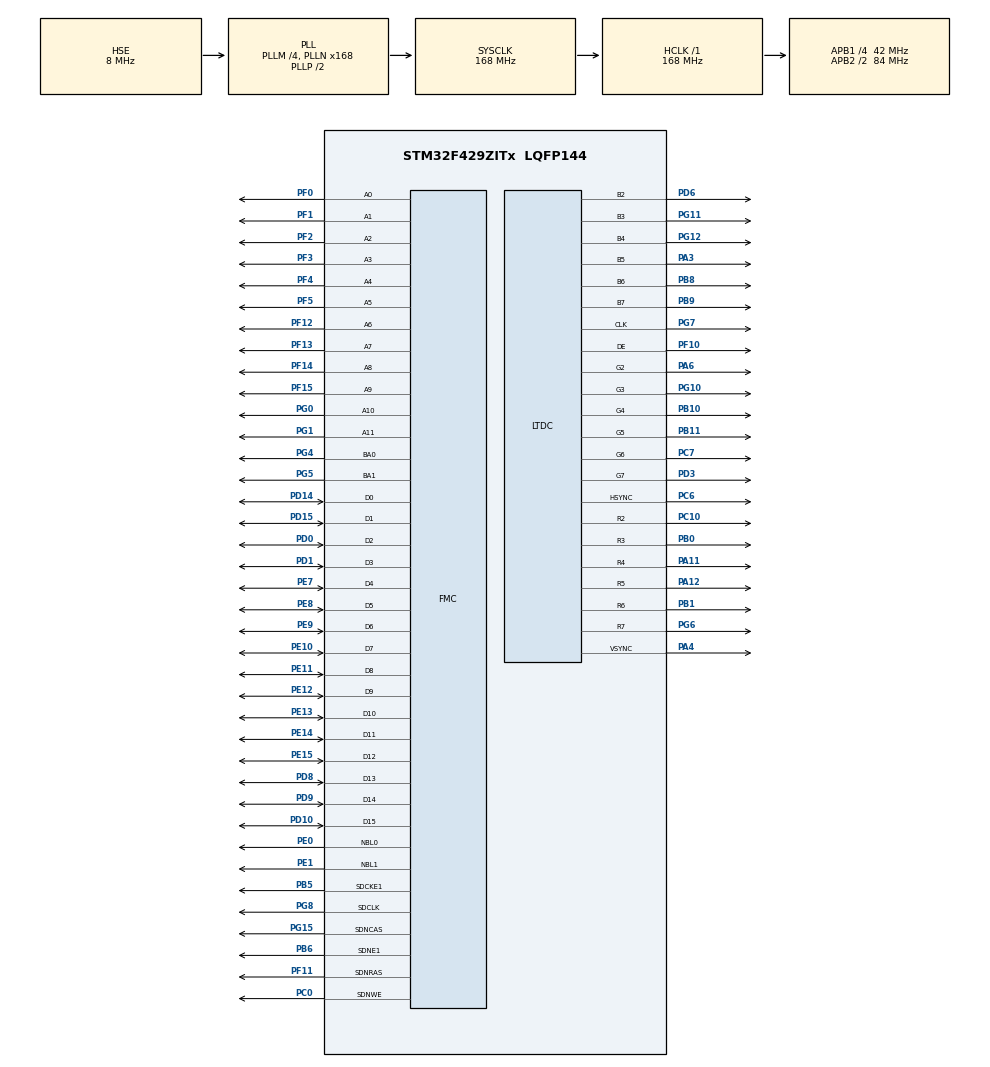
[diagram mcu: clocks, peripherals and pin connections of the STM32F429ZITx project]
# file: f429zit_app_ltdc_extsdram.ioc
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FMC.CASLatency1=FMC_SDRAM_CAS_LATENCY_3
FMC.ExitSelfRefreshDelay1=7
FMC.LoadToActiveDelay1=2
FMC.RCDDelay1=2
FMC.RPDelay1=2
FMC.RPDelay2=2
FMC.ReadPipeDelay1=FMC_SDRAM_RPIPE_DELAY_1
FMC.ReadPipeDelay2=FMC_SDRAM_RPIPE_DELAY_1
FMC.RowCycleDelay1=7
FMC.RowCycleDelay2=7
FMC.SDClockPeriod1=FMC_SDRAM_CLOCK_PERIOD_2
FMC.SDClockPeriod2=FMC_SDRAM_CLOCK_PERIOD_2
FMC.SelfRefreshTime1=4
FMC.WriteRecoveryTime1=3
LTDC.ActiveH=320
LTDC.ActiveW=240
LTDC.Alpha_L0=255
LTDC.BlendingFactor1_L0=LTDC_BLENDING_FACTOR1_PAxCA
LTDC.BlendingFactor2_L0=LTDC_BLENDING_FACTOR2_PAxCA
LTDC.HBP=20
LTDC.HFP=10
LTDC.HSync=10
LTDC.ImageHeight_L0=320
LTDC.ImageWidth_L0=240
LTDC.Layers=0
LTDC.PixelFormat_L0=LTDC_PIXEL_FORMAT_RGB565
LTDC.VFP=4
LTDC.VSync=2
LTDC.WindowX1_L0=240
LTDC.WindowY1_L0=320
Mcu.Family=STM32F4
Mcu.Name=STM32F429ZITx
Mcu.Package=LQFP144
NVIC.PriorityGroup=NVIC_PRIORITYGROUP_4
NVIC.TIM6_DAC_IRQn=true\:0\:0\:false\:false\:true\:false
NVIC.TimeBase=TIM6_DAC_IRQn
NVIC.TimeBaseIP=TIM6
PA11.Mode=RGB666
PA11.Signal=LTDC_R4
PA12.Mode=RGB666
PA12.Signal=LTDC_R5
PA13.Mode=Trace_Asynchronous_SW
PA13.Signal=SYS_JTMS-SWDIO
PA14.Mode=Trace_Asynchronous_SW
PA14.Signal=SYS_JTCK-SWCLK
PA3.Mode=RGB666
PA3.Signal=LTDC_B5
PA4.Mode=RGB666
PA4.Signal=LTDC_VSYNC
PA6.Mode=RGB666
PA6.Signal=LTDC_G2
PB0.Mode=RGB666
PB0.Signal=LTDC_R3
PB1.Mode=RGB666
PB1.Signal=LTDC_R6
PB10.Mode=RGB666
PB10.Signal=LTDC_G4
PB11.Mode=RGB666
PB11.Signal=LTDC_G5
PB3.Mode=Trace_Asynchronous_SW
PB3.Signal=SYS_JTDO-SWO
PB5.Mode=SdramChipSelect2_1
PB5.Signal=FMC_SDCKE1
PB6.Mode=SdramChipSelect2_1
PB6.Signal=FMC_SDNE1
PB8.Mode=RGB666
PB8.Signal=LTDC_B6
PB9.Mode=RGB666
PB9.Signal=LTDC_B7
PC0.Signal=FMC_SDNWE
PC10.Mode=RGB666
PC10.Signal=LTDC_R2
PC6.Mode=RGB666
PC6.Signal=LTDC_HSYNC
PC7.Mode=RGB666
PC7.Signal=LTDC_G6
PD0.Signal=FMC_D2_DA2
PD1.Signal=FMC_D3_DA3
PD10.Signal=FMC_D15_DA15
PD14.Signal=FMC_D0_DA0
PD15.Signal=FMC_D1_DA1
PD3.Mode=RGB666
PD3.Signal=LTDC_G7
PD6.Mode=RGB666
PD6.Signal=LTDC_B2
PD8.Signal=FMC_D13_DA13
PD9.Signal=FMC_D14_DA14
PE0.Signal=FMC_NBL0
PE1.Signal=FMC_NBL1
PE10.Signal=FMC_D7_DA7
PE11.Signal=FMC_D8_DA8
PE12.Signal=FMC_D9_DA9
PE13.Signal=FMC_D10_DA10
PE14.Signal=FMC_D11_DA11
PE15.Signal=FMC_D12_DA12
PE7.Signal=FMC_D4_DA4
PE8.Signal=FMC_D5_DA5
PE9.Signal=FMC_D6_DA6
PF0.Signal=FMC_A0
PF1.Signal=FMC_A1
PF10.Mode=RGB666
PF10.Signal=LTDC_DE
PF11.Signal=FMC_SDNRAS
PF12.Signal=FMC_A6
PF13.Signal=FMC_A7
PF14.Signal=FMC_A8
PF15.Signal=FMC_A9
PF2.Signal=FMC_A2
PF3.Signal=FMC_A3
PF4.Signal=FMC_A4
PF5.Signal=FMC_A5
PG0.Signal=FMC_A10
PG1.Signal=FMC_A11
PG10.Mode=RGB666
PG10.Signal=LTDC_G3
PG11.Mode=RGB666
PG11.Signal=LTDC_B3
PG12.Mode=RGB666
PG12.Signal=LTDC_B4
PG15.Signal=FMC_SDNCAS
PG4.Signal=FMC_A14_BA0
PG5.Signal=FMC_A15_BA1
PG6.Mode=RGB666
PG6.Signal=LTDC_R7
PG7.Mode=RGB666
PG7.Signal=LTDC_CLK
PG8.Signal=FMC_SDCLK
PH0/OSC_IN.Mode=HSE-External-Oscillator
PH0/OSC_IN.Signal=RCC_OSC_IN
PH1/OSC_OUT.Mode=HSE-External-Oscillator
PH1/OSC_OUT.Signal=RCC_OSC_OUT
ProjectManager.HeapSize=0x200
ProjectManager.StackSize=0x800
ProjectManager.TargetToolchain=TrueSTUDIO
RCC.48MHZClocksFreq_Value=84000000
RCC.AHBFreq_Value=168000000
RCC.APB1CLKDivider=RCC_HCLK_DIV4
RCC.APB1Freq_Value=42000000
RCC.APB1TimFreq_Value=84000000
RCC.APB2CLKDivider=RCC_HCLK_DIV2
RCC.APB2Freq_Value=84000000
RCC.APB2TimFreq_Value=168000000
RCC.CortexFreq_Value=168000000
RCC.HCLKFreq_Value=168000000
RCC.HSE_VALUE=8000000
RCC.HSI_VALUE=16000000
RCC.LSE_VALUE=32768
RCC.PLLM=4
RCC.PLLN=168
RCC.PLLSAIDivR=RCC_PLLSAIDIVR_4
RCC.PLLSAIN=60
RCC.PLLSAIR=5
RCC.PLLSourceVirtual=RCC_PLLSOURCE_HSE
RCC.SYSCLKFreq_VALUE=168000000
RCC.SYSCLKSource=RCC_SYSCLKSOURCE_PLLCLK
RCC.VCOOutputFreq_Value=336000000
SH.FMC_A0.0=FMC_A0,12b-sda1
SH.FMC_A1.0=FMC_A1,12b-sda1
SH.FMC_A10.0=FMC_A10,12b-sda1
SH.FMC_A11.0=FMC_A11,12b-sda1
SH.FMC_A14_BA0.0=FMC_BA0,FourSdramBanks1
SH.FMC_A15_BA1.0=FMC_BA1,FourSdramBanks1
SH.FMC_A2.0=FMC_A2,12b-sda1
SH.FMC_A3.0=FMC_A3,12b-sda1
SH.FMC_A4.0=FMC_A4,12b-sda1
SH.FMC_A5.0=FMC_A5,12b-sda1
SH.FMC_A6.0=FMC_A6,12b-sda1
SH.FMC_A7.0=FMC_A7,12b-sda1
SH.FMC_A8.0=FMC_A8,12b-sda1
SH.FMC_A9.0=FMC_A9,12b-sda1
SH.FMC_D0_DA0.0=FMC_D0,sd-16b-d1
SH.FMC_D10_DA10.0=FMC_D10,sd-16b-d1
SH.FMC_D11_DA11.0=FMC_D11,sd-16b-d1
SH.FMC_D12_DA12.0=FMC_D12,sd-16b-d1
SH.FMC_D13_DA13.0=FMC_D13,sd-16b-d1
SH.FMC_D14_DA14.0=FMC_D14,sd-16b-d1
SH.FMC_D15_DA15.0=FMC_D15,sd-16b-d1
SH.FMC_D1_DA1.0=FMC_D1,sd-16b-d1
SH.FMC_D2_DA2.0=FMC_D2,sd-16b-d1
SH.FMC_D3_DA3.0=FMC_D3,sd-16b-d1
SH.FMC_D4_DA4.0=FMC_D4,sd-16b-d1
SH.FMC_D5_DA5.0=FMC_D5,sd-16b-d1
SH.FMC_D6_DA6.0=FMC_D6,sd-16b-d1
SH.FMC_D7_DA7.0=FMC_D7,sd-16b-d1
SH.FMC_D8_DA8.0=FMC_D8,sd-16b-d1
SH.FMC_D9_DA9.0=FMC_D9,sd-16b-d1
SH.FMC_NBL0.0=FMC_NBL0,Sd2ByteEnable1
SH.FMC_NBL1.0=FMC_NBL1,Sd2ByteEnable1
SH.FMC_SDCLK.0=FMC_SDCLK,12b-sda1
SH.FMC_SDNCAS.0=FMC_SDNCAS,12b-sda1
SH.FMC_SDNRAS.0=FMC_SDNRAS,12b-sda1
SH.FMC_SDNWE.0=FMC_SDNWE,12b-sda1
VP_CRC_VS_CRC.Mode=CRC_Activate
VP_DMA2D_VS_DMA2D.Mode=DMA2D_Activate
VP_SYS_VS_tim6.Mode=TIM6
board=custom

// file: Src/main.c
/**
  ******************************************************************************
  * @file           : main.c
  * @brief          : Main program body
  ******************************************************************************
  ** This notice applies to any and all portions of this file
  * that are not between comment pairs USER CODE BEGIN and
  * USER CODE END. Other portions of this file, whether
  * inserted by the user or by software development tools
  * are owned by their respective copyright owners.
  *
  * COPYRIGHT(c) 2020 STMicroelectronics
  *
  * Redistribution and use in source and binary forms, with or without modification,
  * are permitted provided that the following conditions are met:
  *   1. Redistributions of source code must retain the above copyright notice,
  *      this list of conditions and the following disclaimer.
  *   2. Redistributions in binary form must reproduce the above copyright notice,
  *      this list of conditions and the following disclaimer in the documentation
  *      and/or other materials provided with the distribution.
  *   3. Neither the name of STMicroelectronics nor the names of its contributors
  *      may be used to endorse or promote products derived from this software
  *      without specific prior written permission.
  *
  * THIS SOFTWARE IS PROVIDED BY THE COPYRIGHT HOLDERS AND CONTRIBUTORS "AS IS"
  * AND ANY EXPRESS OR IMPLIED WARRANTIES, INCLUDING, BUT NOT LIMITED TO, THE
  * IMPLIED WARRANTIES OF MERCHANTABILITY AND FITNESS FOR A PARTICULAR PURPOSE ARE
  * DISCLAIMED. IN NO EVENT SHALL THE COPYRIGHT HOLDER OR CONTRIBUTORS BE LIABLE
  * FOR ANY DIRECT, INDIRECT, INCIDENTAL, SPECIAL, EXEMPLARY, OR CONSEQUENTIAL
  * DAMAGES (INCLUDING, BUT NOT LIMITED TO, PROCUREMENT OF SUBSTITUTE GOODS OR
  * SERVICES; LOSS OF USE, DATA, OR PROFITS; OR BUSINESS INTERRUPTION) HOWEVER
  * CAUSED AND ON ANY THEORY OF LIABILITY, WHETHER IN CONTRACT, STRICT LIABILITY,
  * OR TORT (INCLUDING NEGLIGENCE OR OTHERWISE) ARISING IN ANY WAY OUT OF THE USE
  * OF THIS SOFTWARE, EVEN IF ADVISED OF THE POSSIBILITY OF SUCH DAMAGE.
  *
  ******************************************************************************
  */
#include "main.h"
#include "stm32f4xx_hal.h"

/* USER CODE BEGIN Includes */
#include "sdinit.h"
/* USER CODE END Includes */

CRC_HandleTypeDef hcrc;

DMA2D_HandleTypeDef hdma2d;

LTDC_HandleTypeDef hltdc;

SDRAM_HandleTypeDef hsdram1;

/* USER CODE BEGIN PV */
/* Private variables ---------------------------------------------------------*/

/* USER CODE END PV */

void SystemClock_Config(void);
static void MX_GPIO_Init(void);
static void MX_FMC_Init(void);
static void MX_DMA2D_Init(void);
static void MX_CRC_Init(void);
static void MX_LTDC_Init(void);

/* USER CODE BEGIN PFP */
/* Private function prototypes -----------------------------------------------*/
void mainApp(void);
/* USER CODE END PFP */

int main(void)
{

  /* MCU Configuration----------------------------------------------------------*/

  /* Reset of all peripherals, Initializes the Flash interface and the Systick. */
  HAL_Init();

  /* Configure the system clock */
  SystemClock_Config();

  /* Initialize all configured peripherals */
  MX_GPIO_Init();
  MX_FMC_Init();
  MX_DMA2D_Init();
  MX_CRC_Init();
  MX_LTDC_Init();
  /* USER CODE BEGIN 2 */
  SDRAM_Initialization_Sequence(&hsdram1);
  /* USER CODE END 2 */

  /* Infinite loop */
  /* USER CODE BEGIN WHILE */
  mainApp();
  while (1)
  {

  /* USER CODE END WHILE */

  }

}

void SystemClock_Config(void)
{

  RCC_OscInitTypeDef RCC_OscInitStruct;
  RCC_ClkInitTypeDef RCC_ClkInitStruct;
  RCC_PeriphCLKInitTypeDef PeriphClkInitStruct;

    /**Configure the main internal regulator output voltage
    */
  __HAL_RCC_PWR_CLK_ENABLE();

  __HAL_PWR_VOLTAGESCALING_CONFIG(PWR_REGULATOR_VOLTAGE_SCALE1);

    /**Initializes the CPU, AHB and APB busses clocks
    */
  RCC_OscInitStruct.OscillatorType = RCC_OSCILLATORTYPE_HSE;
  RCC_OscInitStruct.HSEState = RCC_HSE_ON;
  RCC_OscInitStruct.PLL.PLLState = RCC_PLL_ON;
  RCC_OscInitStruct.PLL.PLLSource = RCC_PLLSOURCE_HSE;
  RCC_OscInitStruct.PLL.PLLM = 4;
  RCC_OscInitStruct.PLL.PLLN = 168;
  RCC_OscInitStruct.PLL.PLLP = RCC_PLLP_DIV2;
  RCC_OscInitStruct.PLL.PLLQ = 4;
  if (HAL_RCC_OscConfig(&RCC_OscInitStruct) != HAL_OK)
  {
    _Error_Handler(__FILE__, __LINE__);
  }

    /**Initializes the CPU, AHB and APB busses clocks
    */
  RCC_ClkInitStruct.ClockType = RCC_CLOCKTYPE_HCLK|RCC_CLOCKTYPE_SYSCLK
                              |RCC_CLOCKTYPE_PCLK1|RCC_CLOCKTYPE_PCLK2;
  RCC_ClkInitStruct.SYSCLKSource = RCC_SYSCLKSOURCE_PLLCLK;
  RCC_ClkInitStruct.AHBCLKDivider = RCC_SYSCLK_DIV1;
  RCC_ClkInitStruct.APB1CLKDivider = RCC_HCLK_DIV4;
  RCC_ClkInitStruct.APB2CLKDivider = RCC_HCLK_DIV2;

  if (HAL_RCC_ClockConfig(&RCC_ClkInitStruct, FLASH_LATENCY_5) != HAL_OK)
  {
    _Error_Handler(__FILE__, __LINE__);
  }

  PeriphClkInitStruct.PeriphClockSelection = RCC_PERIPHCLK_LTDC;
  PeriphClkInitStruct.PLLSAI.PLLSAIN = 60;
  PeriphClkInitStruct.PLLSAI.PLLSAIR = 5;
  PeriphClkInitStruct.PLLSAIDivR = RCC_PLLSAIDIVR_4;
  if (HAL_RCCEx_PeriphCLKConfig(&PeriphClkInitStruct) != HAL_OK)
  {
    _Error_Handler(__FILE__, __LINE__);
  }

    /**Configure the Systick interrupt time
    */
  HAL_SYSTICK_Config(HAL_RCC_GetHCLKFreq()/1000);

    /**Configure the Systick
    */
  HAL_SYSTICK_CLKSourceConfig(SYSTICK_CLKSOURCE_HCLK);

  /* SysTick_IRQn interrupt configuration */
  HAL_NVIC_SetPriority(SysTick_IRQn, 0, 0);
}

/* CRC init function */
static void MX_CRC_Init(void)
{

  hcrc.Instance = CRC;
  if (HAL_CRC_Init(&hcrc) != HAL_OK)
  {
    _Error_Handler(__FILE__, __LINE__);
  }

}

/* DMA2D init function */
static void MX_DMA2D_Init(void)
{

  hdma2d.Instance = DMA2D;
  hdma2d.Init.Mode = DMA2D_M2M;
  hdma2d.Init.ColorMode = DMA2D_OUTPUT_ARGB8888;
  hdma2d.Init.OutputOffset = 0;
  hdma2d.LayerCfg[1].InputOffset = 0;
  hdma2d.LayerCfg[1].InputColorMode = DMA2D_INPUT_ARGB8888;
  hdma2d.LayerCfg[1].AlphaMode = DMA2D_NO_MODIF_ALPHA;
  hdma2d.LayerCfg[1].InputAlpha = 0;
  if (HAL_DMA2D_Init(&hdma2d) != HAL_OK)
  {
    _Error_Handler(__FILE__, __LINE__);
  }

  if (HAL_DMA2D_ConfigLayer(&hdma2d, 1) != HAL_OK)
  {
    _Error_Handler(__FILE__, __LINE__);
  }

}

/* LTDC init function */
static void MX_LTDC_Init(void)
{

  LTDC_LayerCfgTypeDef pLayerCfg;

  hltdc.Instance = LTDC;
  hltdc.Init.HSPolarity = LTDC_HSPOLARITY_AL;
  hltdc.Init.VSPolarity = LTDC_VSPOLARITY_AL;
  hltdc.Init.DEPolarity = LTDC_DEPOLARITY_AL;
  hltdc.Init.PCPolarity = LTDC_PCPOLARITY_IPC;
  hltdc.Init.HorizontalSync = 9;
  hltdc.Init.VerticalSync = 1;
  hltdc.Init.AccumulatedHBP = 29;
  hltdc.Init.AccumulatedVBP = 3;
  hltdc.Init.AccumulatedActiveW = 269;
  hltdc.Init.AccumulatedActiveH = 323;
  hltdc.Init.TotalWidth = 279;
  hltdc.Init.TotalHeigh = 327;
  hltdc.Init.Backcolor.Blue = 0;
  hltdc.Init.Backcolor.Green = 0;
  hltdc.Init.Backcolor.Red = 0;
  if (HAL_LTDC_Init(&hltdc) != HAL_OK)
  {
    _Error_Handler(__FILE__, __LINE__);
  }

  pLayerCfg.WindowX0 = 0;
  pLayerCfg.WindowX1 = 240;
  pLayerCfg.WindowY0 = 0;
  pLayerCfg.WindowY1 = 320;
  pLayerCfg.PixelFormat = LTDC_PIXEL_FORMAT_RGB565;
  pLayerCfg.Alpha = 255;
  pLayerCfg.Alpha0 = 0;
  pLayerCfg.BlendingFactor1 = LTDC_BLENDING_FACTOR1_PAxCA;
  pLayerCfg.BlendingFactor2 = LTDC_BLENDING_FACTOR2_PAxCA;
  pLayerCfg.FBStartAdress = 0;
  pLayerCfg.ImageWidth = 240;
  pLayerCfg.ImageHeight = 320;
  pLayerCfg.Backcolor.Blue = 0;
  pLayerCfg.Backcolor.Green = 0;
  pLayerCfg.Backcolor.Red = 0;
  if (HAL_LTDC_ConfigLayer(&hltdc, &pLayerCfg, 0) != HAL_OK)
  {
    _Error_Handler(__FILE__, __LINE__);
  }

}

/* FMC initialization function */
static void MX_FMC_Init(void)
{
  FMC_SDRAM_TimingTypeDef SdramTiming;

  /** Perform the SDRAM1 memory initialization sequence
  */
  hsdram1.Instance = FMC_SDRAM_DEVICE;
  /* hsdram1.Init */
  hsdram1.Init.SDBank = FMC_SDRAM_BANK2;
  hsdram1.Init.ColumnBitsNumber = FMC_SDRAM_COLUMN_BITS_NUM_8;
  hsdram1.Init.RowBitsNumber = FMC_SDRAM_ROW_BITS_NUM_12;
  hsdram1.Init.MemoryDataWidth = FMC_SDRAM_MEM_BUS_WIDTH_16;
  hsdram1.Init.InternalBankNumber = FMC_SDRAM_INTERN_BANKS_NUM_4;
  hsdram1.Init.CASLatency = FMC_SDRAM_CAS_LATENCY_3;
  hsdram1.Init.WriteProtection = FMC_SDRAM_WRITE_PROTECTION_DISABLE;
  hsdram1.Init.SDClockPeriod = FMC_SDRAM_CLOCK_PERIOD_2;
  hsdram1.Init.ReadBurst = FMC_SDRAM_RBURST_DISABLE;
  hsdram1.Init.ReadPipeDelay = FMC_SDRAM_RPIPE_DELAY_1;
  /* SdramTiming */
  SdramTiming.LoadToActiveDelay = 2;
  SdramTiming.ExitSelfRefreshDelay = 7;
  SdramTiming.SelfRefreshTime = 4;
  SdramTiming.RowCycleDelay = 7;
  SdramTiming.WriteRecoveryTime = 3;
  SdramTiming.RPDelay = 2;
  SdramTiming.RCDDelay = 2;

  if (HAL_SDRAM_Init(&hsdram1, &SdramTiming) != HAL_OK)
  {
    _Error_Handler(__FILE__, __LINE__);
  }

}

/** Configure pins as
        * Analog
        * Input
        * Output
        * EVENT_OUT
        * EXTI
*/
static void MX_GPIO_Init(void)
{

  /* GPIO Ports Clock Enable */
  __HAL_RCC_GPIOF_CLK_ENABLE();
  __HAL_RCC_GPIOH_CLK_ENABLE();
  __HAL_RCC_GPIOC_CLK_ENABLE();
  __HAL_RCC_GPIOA_CLK_ENABLE();
  __HAL_RCC_GPIOB_CLK_ENABLE();
  __HAL_RCC_GPIOG_CLK_ENABLE();
  __HAL_RCC_GPIOE_CLK_ENABLE();
  __HAL_RCC_GPIOD_CLK_ENABLE();

}

void HAL_TIM_PeriodElapsedCallback(TIM_HandleTypeDef *htim)
{
  if (htim->Instance == TIM6) {
    HAL_IncTick();
  }
}

void _Error_Handler(char *file, int line)
{
  while(1)
  {
  }
}

/************************ (C) COPYRIGHT STMicroelectronics *****END OF FILE****/
